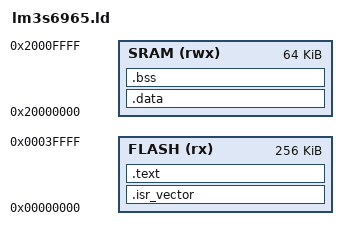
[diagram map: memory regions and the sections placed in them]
/* Linker script for LM3S6965 (Cortex-M3) — QEMU machine "lm3s6965evb".
 * Flash 256K @ 0x00000000, SRAM 64K @ 0x20000000. */
ENTRY(Reset_Handler)

MEMORY
{
  FLASH (rx) : ORIGIN = 0x00000000, LENGTH = 256K
  SRAM (rwx) : ORIGIN = 0x20000000, LENGTH = 64K
}

_estack = ORIGIN(SRAM) + LENGTH(SRAM);

SECTIONS
{
  .isr_vector : { KEEP(*(.isr_vector)) } > FLASH

  .text : {
    *(.text*)
    *(.rodata*)
    . = ALIGN(4);
    _etext = .;
  } > FLASH

  .data : AT (_etext) {
    . = ALIGN(4);
    _sdata = .;
    *(.data*)
    . = ALIGN(4);
    _edata = .;
  } > SRAM
  _sidata = LOADADDR(.data);

  .bss : {
    . = ALIGN(4);
    _sbss = .;
    *(.bss*)
    *(COMMON)
    . = ALIGN(4);
    _ebss = .;
  } > SRAM

  /DISCARD/ : { *(.ARM.exidx*) *(.ARM.extab*) }
}
